# ATmega1280 register map
Vendor: Atmel; File version: 1.0
CPU: other r0p0, little endian, no MPU, no FPU, 4 interrupt priority bits
Registers are 8-bit, read-write, reset 0x0 unless marked. A register's access mark holds for its fields unless they carry their own. Offsets are from the block's base; [hi:lo] are bit positions.

## USART1 — USART
Base 0x008000C8
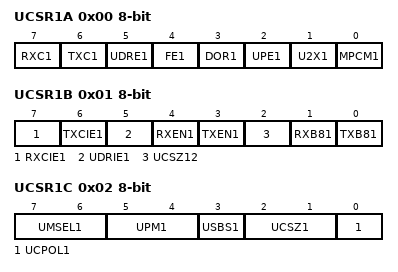
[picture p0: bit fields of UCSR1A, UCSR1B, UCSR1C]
0x00 UCSR1A — USART Control and Status Register A (read-only for debugger)
  [7] RXC1 — USART Receive Complete
  [6] TXC1 — USART Transmit Complete
  [5] UDRE1 — USART Data Register Empty
  [4] FE1 — Framing Error
  [3] DOR1 — Data overRun
  [2] UPE1 — Parity Error
  [1] U2X1 — Double the USART transmission speed
  [0] MPCM1 — Multi-processor Communication Mode
0x01 UCSR1B — USART Control and Status Register B
  [7] RXCIE1 — RX Complete Interrupt Enable
  [6] TXCIE1 — TX Complete Interrupt Enable
  [5] UDRIE1 — USART Data register Empty Interrupt Enable
  [4] RXEN1 — Receiver Enable
  [3] TXEN1 — Transmitter Enable
  [2] UCSZ12 — Character Size
  [1] RXB81 — Receive Data Bit 8
  [0] TXB81 — Transmit Data Bit 8
0x02 UCSR1C — USART Control and Status Register C
  [7:6] UMSEL1 — USART Mode Select
    0=ASYNCHRONOUS_USART; 1=SYNCHRONOUS_USART; 3=MASTER_SPI
  [5:4] UPM1 — Parity Mode Bits
    0=DISABLED; 2=ENABLED_EVEN_PARITY; 3=ENABLED_ODD_PARITY
  [3] USBS1 — Stop Bit Select
    0=1_BIT; 1=2_BIT
  [2:1] UCSZ1 — Character Size
  [0] UCPOL1 — Clock Polarity
0x04 UBRR1 16-bit (reset mask 0xFF) — USART Baud Rate Register Bytes
0x06 UDR1 — USART I/O Data Register (write-only for debugger)

## USART2 — USART
Base 0x008000D0
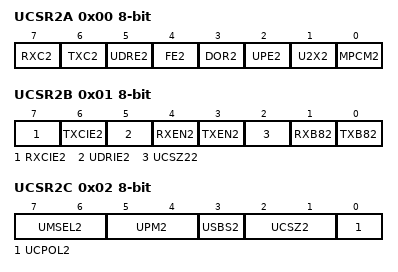
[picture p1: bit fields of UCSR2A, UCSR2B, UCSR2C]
0x00 UCSR2A — USART Control and Status Register A (read-only for debugger)
  [7] RXC2 — USART Receive Complete
  [6] TXC2 — USART Transmit Complete
  [5] UDRE2 — USART Data Register Empty
  [4] FE2 — Framing Error
  [3] DOR2 — Data overRun
  [2] UPE2 — Parity Error
  [1] U2X2 — Double the USART transmission speed
  [0] MPCM2 — Multi-processor Communication Mode
0x01 UCSR2B — USART Control and Status Register B
  [7] RXCIE2 — RX Complete Interrupt Enable
  [6] TXCIE2 — TX Complete Interrupt Enable
  [5] UDRIE2 — USART Data register Empty Interrupt Enable
  [4] RXEN2 — Receiver Enable
  [3] TXEN2 — Transmitter Enable
  [2] UCSZ22 — Character Size
  [1] RXB82 — Receive Data Bit 8
  [0] TXB82 — Transmit Data Bit 8
0x02 UCSR2C — USART Control and Status Register C
  [7:6] UMSEL2 — USART Mode Select
    0=ASYNCHRONOUS_USART; 1=SYNCHRONOUS_USART; 3=MASTER_SPI
  [5:4] UPM2 — Parity Mode Bits
    0=DISABLED; 2=ENABLED_EVEN_PARITY; 3=ENABLED_ODD_PARITY
  [3] USBS2 — Stop Bit Select
    0=1_BIT; 1=2_BIT
  [2:1] UCSZ2 — Character Size
  [0] UCPOL2 — Clock Polarity
0x04 UBRR2 16-bit (reset mask 0xFF) — USART Baud Rate Register Bytes
0x06 UDR2 — USART I/O Data Register (write-only for debugger)

## USART3 — USART
Base 0x00800130
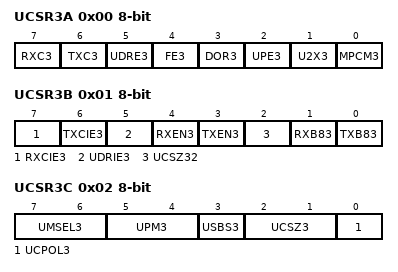
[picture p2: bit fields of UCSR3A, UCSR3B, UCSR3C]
0x00 UCSR3A — USART Control and Status Register A (read-only for debugger)
  [7] RXC3 — USART Receive Complete
  [6] TXC3 — USART Transmit Complete
  [5] UDRE3 — USART Data Register Empty
  [4] FE3 — Framing Error
  [3] DOR3 — Data overRun
  [2] UPE3 — Parity Error
  [1] U2X3 — Double the USART transmission speed
  [0] MPCM3 — Multi-processor Communication Mode
0x01 UCSR3B — USART Control and Status Register B
  [7] RXCIE3 — RX Complete Interrupt Enable
  [6] TXCIE3 — TX Complete Interrupt Enable
  [5] UDRIE3 — USART Data register Empty Interrupt Enable
  [4] RXEN3 — Receiver Enable
  [3] TXEN3 — Transmitter Enable
  [2] UCSZ32 — Character Size
  [1] RXB83 — Receive Data Bit 8
  [0] TXB83 — Transmit Data Bit 8
0x02 UCSR3C — USART Control and Status Register C
  [7:6] UMSEL3 — USART Mode Select
    0=ASYNCHRONOUS_USART; 1=SYNCHRONOUS_USART; 3=MASTER_SPI
  [5:4] UPM3 — Parity Mode Bits
    0=DISABLED; 2=ENABLED_EVEN_PARITY; 3=ENABLED_ODD_PARITY
  [3] USBS3 — Stop Bit Select
    0=1_BIT; 1=2_BIT
  [2:1] UCSZ3 — Character Size
  [0] UCPOL3 — Clock Polarity
0x04 UBRR3 16-bit (reset mask 0xFF) — USART Baud Rate Register Bytes
0x06 UDR3 — USART I/O Data Register (write-only for debugger)

## WDT — Watchdog Timer
Base 0x00800060
0x00 WDTCSR — Watchdog Timer Control Register (read-only for debugger)
  [7] WDIF — Watchdog Timeout Interrupt Flag
  [6] WDIE — Watchdog Timeout Interrupt Enable
  [4] WDCE — Watchdog Change Enable
  [3] WDE — Watch Dog Enable
  [5:0] WDP — Watchdog Timer Prescaler Bits
    0=OSCILLATOR_CYCLES_2K; 1=OSCILLATOR_CYCLES_4K; 2=OSCILLATOR_CYCLES_8K; 3=OSCILLATOR_CYCLES_16K; 4=OSCILLATOR_CYCLES_32K; 5=OSCILLATOR_CYCLES_64K; 6=OSCILLATOR_CYCLES_128K; 7=OSCILLATOR_CYCLES_256K
